# R7KA8D2AD register map
Vendor: Renesas Electronics Corporation; Series: RA8; File version: 1.10.02
CPU: CM85 r0p2, little endian, MPU, FPU, VTOR, 4 interrupt priority bits, 96 interrupts
Registers are 32-bit, read-write, reset 0x0 unless marked. A register's access mark holds for its fields unless they carry their own. Offsets are from the block's base; [hi:lo] are bit positions; {n}, {i} and the like mark numbered series; 'fields as' and 'values as' point back to an identical list.

## CPSCU — CPU System Security Control Unit
Base 0x40008000
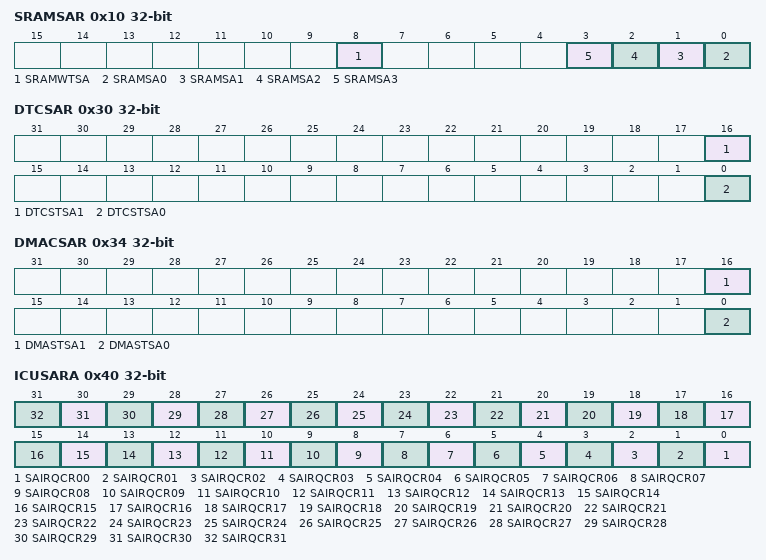
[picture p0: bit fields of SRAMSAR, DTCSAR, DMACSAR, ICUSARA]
0x10 SRAMSAR — SRAM Security Attribution Register
  [all] fields
    0=Secure; 1=Non-Secure
  [8] SRAMWTSA — SRAMWTSC Security Attribution
  [n] SRAMSA{n} (n=0..3) — SRAM{n} Register Security Attribution
0x30 DTCSAR — DTC Controller Security Attribution Register
  [16] DTCSTSA1 — DTC1 Security Attribution
    0=Secure; 1=Non-secure
  [0] DTCSTSA0 — DTC0 Security Attribution
    0=Secure; 1=Non-secure
0x34 DMACSAR — DMAC Controller Security Attribution Register
  [16] DMASTSA1 — DMAC1 DMAST Security Attribution
    0=Secure; 1=Non-secure
  [0] DMASTSA0 — DMAC0 DMAST Security Attribution
    0=Secure; 1=Non-secure
0x40 ICUSARA — Interrupt Controller Unit Security Attribution Register A
  [all] fields
    0=Secure; 1=Non-Secure
  [n] SAIRQCR{n:02} (n=0..31) — Security attributes of registers for the IRQCR, WUPEN0, WUPEN1 registers
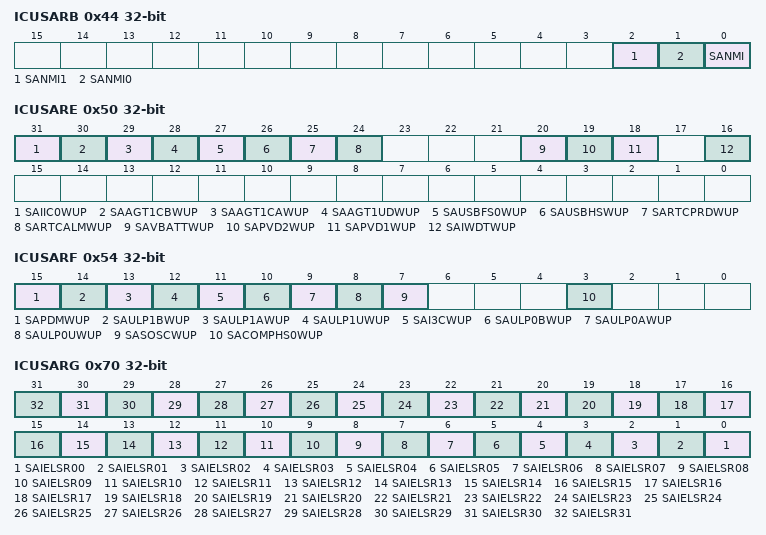
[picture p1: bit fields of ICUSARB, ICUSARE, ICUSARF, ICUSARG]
0x44 ICUSARB — Interrupt Controller Unit Security Attribution Register B
  [all] fields
    0=Secure; 1=Non-Secure
  [2] SANMI1 — Security attributes of the ICU1.NMISR, ICU1.NMIER, ICU1.NMICLR registers
  [1] SANMI0 — Security attributes of the ICU0.NMISR, ICU0.NMIER, ICU0.NMICLR registers
  [0] SANMI — Security attributes of the NMICR register
0x50 ICUSARE — Interrupt Controller Unit Security Attribution Register E
  [all] fields
    0=Secure; 1=Non-Secure
  [31] SAIIC0WUP — Security attributes of registers for WUPEN0.b31
  [30] SAAGT1CBWUP — Security attributes of registers for WUPEN0.b30
  [29] SAAGT1CAWUP — Security attributes of registers for WUPEN0.b29
  [28] SAAGT1UDWUP — Security attributes of registers for WUPEN0.b28
  [27] SAUSBFS0WUP — Security attributes of registers for WUPEN0.b27
  [26] SAUSBHSWUP — Security attributes of registers for WUPEN0.b26
  [25] SARTCPRDWUP — Security attributes of registers for WUPEN0.b25
  [24] SARTCALMWUP — Security attributes of registers for WUPEN0.b24
  [20] SAVBATTWUP — Security attributes of registers for WUPEN0.b20
  [19] SAPVD2WUP — Security attributes of registers for WUPEN0.b19
  [18] SAPVD1WUP — Security attributes of registers for WUPEN0.b18
  [16] SAIWDTWUP — Security attributes of registers for WUPEN0.b16
0x54 ICUSARF — Interrupt Controller Unit Security Attribution Register F
  [all] fields
    0=Secure; 1=Non-Secure
  [15] SAPDMWUP — Security attributes of registers for WUPEN1.b15
  [14] SAULP1BWUP — Security attributes of registers for WUPEN1.b14
  [13] SAULP1AWUP — Security attributes of registers for WUPEN1.b13
  [12] SAULP1UWUP — Security attributes of registers for WUPEN1.b12
  [11] SAI3CWUP — Security attributes of registers for WUPEN1.b11
  [10] SAULP0BWUP — Security attributes of registers for WUPEN1.b10
  [9] SAULP0AWUP — Security attributes of registers for WUPEN1.b9
  [8] SAULP0UWUP — Security attributes of registers for WUPEN1.b8
  [7] SASOSCWUP — Security attributes of registers for WUPEN1.b7
  [3] SACOMPHS0WUP — Security attributes of registers for WUPEN1.b3
0x70 ICUSARG — Interrupt Controller Unit Security Attribution Register G
  [all] fields
    0=Secure; 1=Non-Secure
  [n] SAIELSR{n:02} (n=0..31) — Security attributes of registers for ICU0 event link setting0
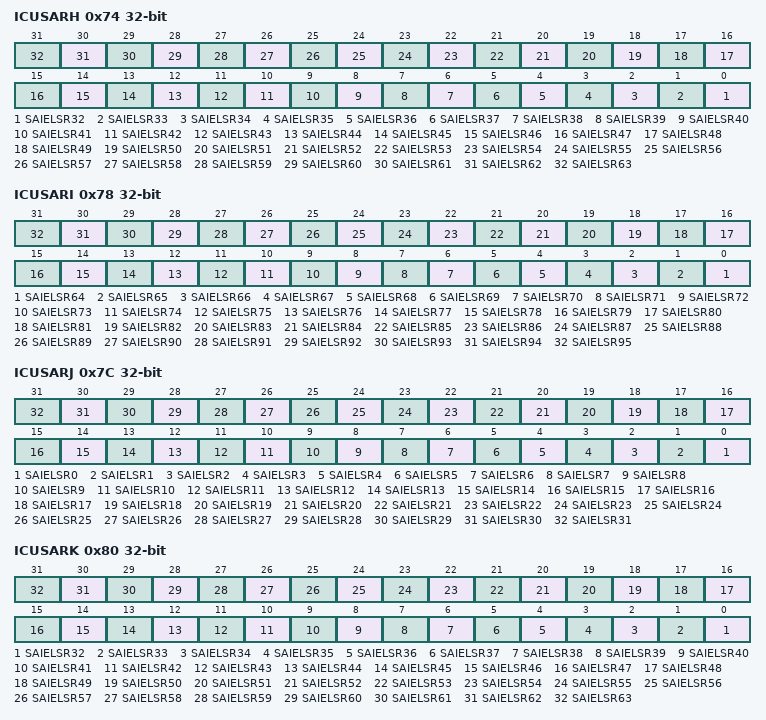
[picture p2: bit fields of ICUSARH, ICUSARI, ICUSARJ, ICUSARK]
0x74 ICUSARH — Interrupt Controller Unit Security Attribution Register H
  [all] fields
    0=Secure; 1=Non-Secure
  [n-32] SAIELSR{n} (n=32..63) — Security attributes of registers for ICU0event link setting1.
0x78 ICUSARI — Interrupt Controller Unit Security Attribution Register I
  [all] fields
    0=Secure; 1=Non-Secure
  [n-64] SAIELSR{n} (n=64..95) — Security attributes of registers for ICU0 event link setting2.
0x7C ICUSARJ — Interrupt Controller Unit Security Attribution Register J
  [all] fields
    0=Secure; 1=Non-Secure
  [n] SAIELSR{n} (n=0..31) — Security attributes of registers for ICU1 event link setting0.
0x80 ICUSARK — Interrupt Controller Unit Security Attribution Register K
  [all] fields
    0=Secure; 1=Non-Secure
  [n-32] SAIELSR{n} (n=32..63) — Security attributes of registers for ICU1 event link setting1
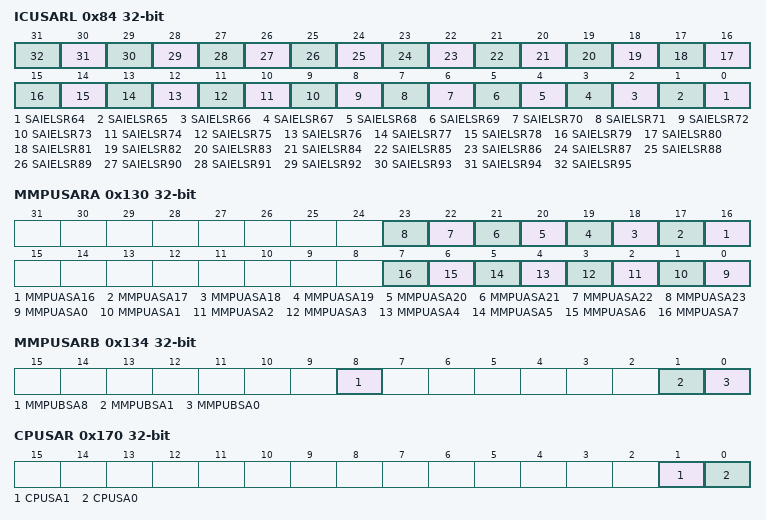
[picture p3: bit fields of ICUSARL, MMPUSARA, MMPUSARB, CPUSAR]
0x84 ICUSARL — Interrupt Controller Unit Security Attribution Register L
  [all] fields
    0=Secure; 1=Non-Secure
  [n-64] SAIELSR{n} (n=64..95) — Security attributes of registers for ICU1 event link setting2.
0x100 BUSSARA — Bus Security Attribution Register A
  [0] BUSSA0 — Bus Security Attribution A0
    0=Secure; 1=Non-secure
0x104 BUSSARB — Bus Security Attribution Register B
  [0] BUSSB0 — Bus Security Attribution B0
    0=Secure; 1=Non-secure
0x110 BUSSARC — Bus Security Attribution Register C
  [0] BUSSC0 — Bus Security Attribution C0
    0=Secure; 1=Non-secure
0x114 BUSPARC reset 0xFFFFFFFF — Bus Privileged Attribution Register C
  [0] BUSPA0 — External bus controller privilege attribution
    0=Privileged; 1=Unprivileged
0x130 MMPUSARA — Master Memory Protection Unit Security Attribution Register A
  [all] fields
    0=Secure; 1=Non-secure
  [n] MMPUASA{n} (n=16..23) — MMPUAn Security Attribution (n = 16 to 23)
  [n] MMPUASA{n} (n=0..7) — MMPUAn Security Attribution (n = 0 to 7)
0x134 MMPUSARB — Master Memory Protection Unit Security Attribution Register B
  [all] fields
    0=Secure; 1=Non-secure
  [8] MMPUBSA8 — MMPUB8 Security Attribution
  [1] MMPUBSA1 — MMPUB1 Security Attribution
  [0] MMPUBSA0 — MMPUB0 Security Attribution
0x170 CPUSAR — CPU Security Attribution Register
  [1] CPUSA1 — CPU Security Attribution 1 (CPU1)
    0=Secure; 1=Non-secure
  [0] CPUSA0 — CPU Security Attribution 0 (CPU0)
    0=Secure; 1=Non-secure
0x180 DEBUGSAR — Debug Security Attribution Register
  [0] DBGSA0 — Debug Security Attribution 0
    0=Secure; 1=Non-secure
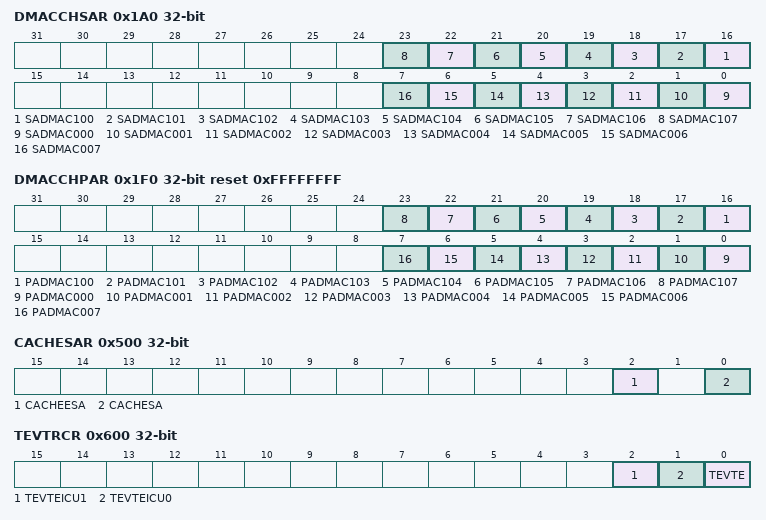
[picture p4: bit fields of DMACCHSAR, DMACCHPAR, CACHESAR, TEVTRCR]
0x1A0 DMACCHSAR — DMA Channel Security Attribution Register
  [all] fields
    0=Secure; 1=Non-secure
  [n-84] SADMAC{n} (n=100..107) — Security attributes of output and registers for DMAC1 channel
  [n] SADMAC{n:03} (n=0..7) — Security attributes of output and registers for DMAC0 channel
0x1F0 DMACCHPAR reset 0xFFFFFFFF — DMA Channel Privilege Attribution Register
  [all] fields
    0=Privileged; 1=Unprivileged
  [n-84] PADMAC{n} (n=100..107) — Privilege attributes of outputs and registers for DMAC1 channel
  [n] PADMAC{n:03} (n=0..7) — Privilege attributes of outputs and registers for DMAC0 channel
{0x400+4i} SRAMSABAR{i} (i=0..3) reset 0x1FE000 — SRAM Security Attribute Boundary Address Register (n = 0 to 3)
0x500 CACHESAR — Cache Security Attribution Register
  [2] CACHEESA — Security attributes of registers for cache error
    0=Secure; 1=Non-Secure
  [0] CACHESA — Security attributes of registers for cache control
    0=Secure; 1=Non-Secure
0x504 TCMSAR — TCM Security Attribution Register
  [0] TCMSA — Security attributes of registers for TCM control
    0=Secure; 1=Non-Secure
0x508 TCMSABARC reset 0x7E000 — TCM Security Attribute Boundary Address Register
  [18:13] TCMSABA — Boundary address between secure and non-secure (start address of non-secure region).
0x50C TCMSABARS reset 0x7E000 — TCM Security Attribute Boundary Address Register
  fields as TCMSABARC
0x510 SRAMESAR — SRAM ECC region Security Attribute Register
  [0] SRAMESA — ECC region Security Attribution
    0=Secure; 1=Non-Secure
0x600 TEVTRCR — Trusted Event Route Control Register
  [all] fields
    0=Disable; 1=Enable
  [2] TEVTEICU1 — Trusted Event Route Control Register for ICU1
  [1] TEVTEICU0 — Trusted Event Route Control Register for ICU0
  [0] TEVTE — Trusted Event Route Control Register for ELC
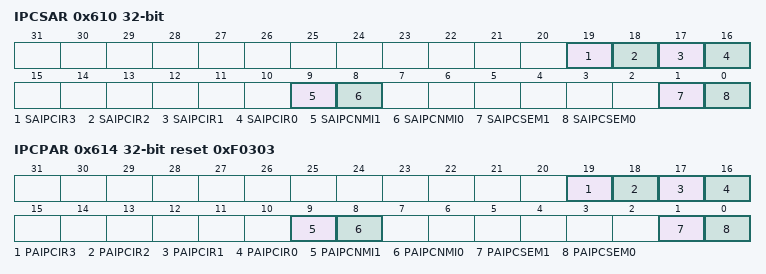
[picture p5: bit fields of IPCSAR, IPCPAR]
0x610 IPCSAR — IPC Security Attribution Register
  [all] fields
    0=Secure; 1=Non-secure
  [19] SAIPCIR3 — Security attributes of registers for IPC1STA1, IPC1ISET1, IPC1TXD1, IPC1RXD1 and IPC1CLR1
  [18] SAIPCIR2 — Security attributes of registers for IPC1STA0, IPC1ISET0, IPC1TXD0, IPC1RXD0 and IPC1CLR0
  [17] SAIPCIR1 — Security attributes of registers for IPC0STA1, IPC0ISET1, IPC0TXD1, IPC0RXD1 and IPC0CLR1
  [16] SAIPCIR0 — Security attributes of registers for IPC0STA0, IPC0ISET0, IPC0TXD0, IPC0RXD0 and IPC0CLR0
  [9] SAIPCNMI1 — Security attributes of IPC1NMISTA, IPC1NMISET and IPC1NMICLR
  [8] SAIPCNMI0 — Security attributes of IPC0NMISTA, IPC0NMISET and IPC0NMICLR
  [1] SAIPCSEM1 — Security attributes of registers for IPCSEMn (n = 8 to 15)
  [0] SAIPCSEM0 — Security attributes of registers for IPCSEMn (n = 0 to 7)
0x614 IPCPAR reset 0xF0303 — IPC Privileged Attribution Register
  [all] fields
    0=Privileged; 1=Unprivileged
  [19] PAIPCIR3 — Privileged attributes of registers for IPC1STA1, IPC1ISET1, IPC1TXD1, IPC1RXD1 and IPC1CLR1
  [18] PAIPCIR2 — Privileged attributes of registers for IPC1STA0, IPC1ISET0, IPC1TXD0, IPC1RXD0 and IPC1CLR0
  [17] PAIPCIR1 — Privileged attributes of registers for IPC0STA1, IPC0ISET1, IPC0TXD1, IPC0RXD1 and IPC0CLR1
  [16] PAIPCIR0 — Privileged attributes of registers for IPC0STA0, IPC0ISET0, IPC0TXD0, IPC0RXD0 and IPC0CLR0
  [9] PAIPCNMI1 — Privileged attributes of registers for IPC1NMISTA, IPC1NMISET and IPC1NMICLR
  [8] PAIPCNMI0 — Privileged attributes of registers for IPC0NMISTA, IPC0NMISET and IPC0NMICLR
  [1] PAIPCSEM1 — Privileged attributes of registers for IPCSEMn (n = 8 to 15)
  [0] PAIPCSEM0 — Privileged attributes of registers for IPCSEMn (n = 0 to 7)

## CPSCU_NS — CPU System Security Control Unit
Base 0x50008000
Registers as CPSCU, without DEBUGSAR, TCMSAR, TCMSABARC, TCMSABARS.
